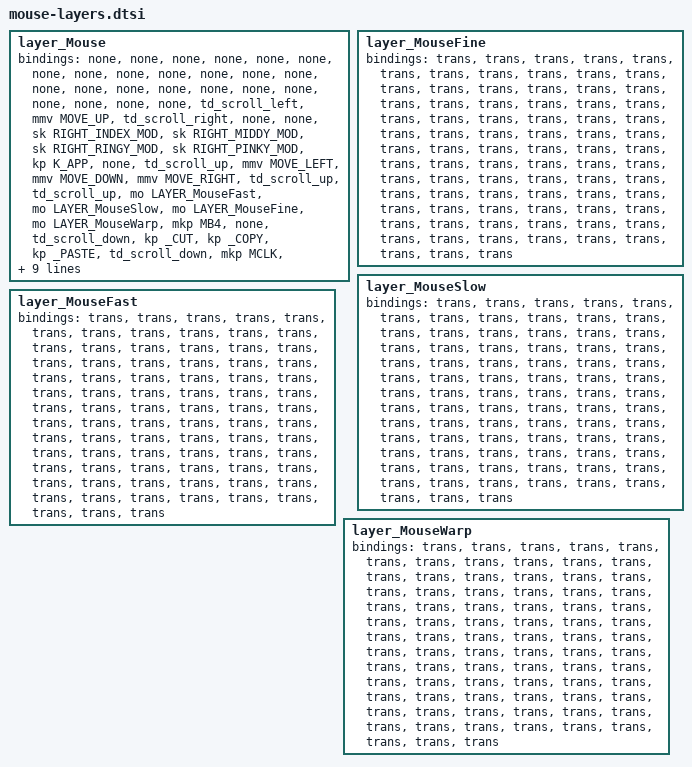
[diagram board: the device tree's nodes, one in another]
        layer_Mouse {
            bindings = <
  &none                   &none                &none                &none                 &none                                                                                                                                      &none                &none                    &none                &none      &none
  &none                   &none                &none                &none                 &none                &none                                                                                             &none                   &none                &none                    &none                &none      &none
  &none                   &none  &td_scroll_left         &mmv MOVE_UP  &td_scroll_right                &none                                                                                             &none     &sk RIGHT_INDEX_MOD  &sk RIGHT_MIDDY_MOD      &sk RIGHT_RINGY_MOD  &sk RIGHT_PINKY_MOD  &kp K_APP
  &none      &td_scroll_up       &mmv MOVE_LEFT       &mmv MOVE_DOWN       &mmv MOVE_RIGHT      &td_scroll_up                                                                              &td_scroll_up     &mo LAYER_MouseFast  &mo LAYER_MouseSlow      &mo LAYER_MouseFine  &mo LAYER_MouseWarp   &mkp MB4
  &none    &td_scroll_down             &kp _CUT            &kp _COPY            &kp _PASTE    &td_scroll_down  &mkp MCLK  &kp K_APP  &mkp MB5  &kp _PASTE         &kp _COPY  &kp _PASTE    &td_scroll_down    &td_scroll_left         &mmv MOVE_UP    &td_scroll_right            &mkp LCLK   &mkp MB5
  &none     &mo LAYER_MouseWarp  &mo LAYER_MouseFine  &mo LAYER_MouseSlow   &mo LAYER_MouseFast                          &mkp LCLK  &mkp RCLK  &mkp MB4       &none  &tog LAYER_Mouse       &none                             &mmv MOVE_LEFT       &mmv MOVE_DOWN          &mmv MOVE_RIGHT            &mkp RCLK  &mkp MCLK
            >;
        };

        layer_MouseFine {
            bindings = <
 &trans  &trans  &trans  &trans  &trans                                                                  &trans  &trans  &trans  &trans  &trans
 &trans  &trans  &trans  &trans  &trans  &trans                                                  &trans  &trans  &trans  &trans  &trans  &trans
 &trans  &trans  &trans  &trans  &trans  &trans                                                  &trans  &trans  &trans  &trans  &trans  &trans
 &trans  &trans  &trans  &trans  &trans  &trans                                                  &trans  &trans  &trans  &trans  &trans  &trans
 &trans  &trans  &trans  &trans  &trans  &trans  &trans  &trans  &trans  &trans  &trans  &trans  &trans  &trans  &trans  &trans  &trans  &trans
 &trans  &trans  &trans  &trans  &trans          &trans  &trans  &trans  &trans  &trans  &trans          &trans  &trans  &trans  &trans  &trans
            >;
        };

        layer_MouseSlow {
            bindings = <
 &trans  &trans  &trans  &trans  &trans                                                                  &trans  &trans  &trans  &trans  &trans
 &trans  &trans  &trans  &trans  &trans  &trans                                                  &trans  &trans  &trans  &trans  &trans  &trans
 &trans  &trans  &trans  &trans  &trans  &trans                                                  &trans  &trans  &trans  &trans  &trans  &trans
 &trans  &trans  &trans  &trans  &trans  &trans                                                  &trans  &trans  &trans  &trans  &trans  &trans
 &trans  &trans  &trans  &trans  &trans  &trans  &trans  &trans  &trans  &trans  &trans  &trans  &trans  &trans  &trans  &trans  &trans  &trans
 &trans  &trans  &trans  &trans  &trans          &trans  &trans  &trans  &trans  &trans  &trans          &trans  &trans  &trans  &trans  &trans
            >;
        };

        layer_MouseFast {
            bindings = <
 &trans  &trans  &trans  &trans  &trans                                                                  &trans  &trans  &trans  &trans  &trans
 &trans  &trans  &trans  &trans  &trans  &trans                                                  &trans  &trans  &trans  &trans  &trans  &trans
 &trans  &trans  &trans  &trans  &trans  &trans                                                  &trans  &trans  &trans  &trans  &trans  &trans
 &trans  &trans  &trans  &trans  &trans  &trans                                                  &trans  &trans  &trans  &trans  &trans  &trans
 &trans  &trans  &trans  &trans  &trans  &trans  &trans  &trans  &trans  &trans  &trans  &trans  &trans  &trans  &trans  &trans  &trans  &trans
 &trans  &trans  &trans  &trans  &trans          &trans  &trans  &trans  &trans  &trans  &trans          &trans  &trans  &trans  &trans  &trans
            >;
        };

        layer_MouseWarp {
            bindings = <
 &trans  &trans  &trans  &trans  &trans                                                                  &trans  &trans  &trans  &trans  &trans
 &trans  &trans  &trans  &trans  &trans  &trans                                                  &trans  &trans  &trans  &trans  &trans  &trans
 &trans  &trans  &trans  &trans  &trans  &trans                                                  &trans  &trans  &trans  &trans  &trans  &trans
 &trans  &trans  &trans  &trans  &trans  &trans                                                  &trans  &trans  &trans  &trans  &trans  &trans
 &trans  &trans  &trans  &trans  &trans  &trans  &trans  &trans  &trans  &trans  &trans  &trans  &trans  &trans  &trans  &trans  &trans  &trans
 &trans  &trans  &trans  &trans  &trans          &trans  &trans  &trans  &trans  &trans  &trans          &trans  &trans  &trans  &trans  &trans
            >;
        };
